# ISP_SBL register map
Vendor: Texas Instruments
Peripheral module from a debugger description file (folder omap36xx).
Registers are 32-bit, read-only, reset 0x0 unless marked. A register's access mark holds for its fields unless they carry their own. Offsets are as the file gives them; lines under a group give offsets from that group; [hi:lo] are bit positions; {n}, {i} and the like mark numbered series; 'fields as' and 'values as' point back to an identical list; <NAME> marks a mode.

## ISP_SBL
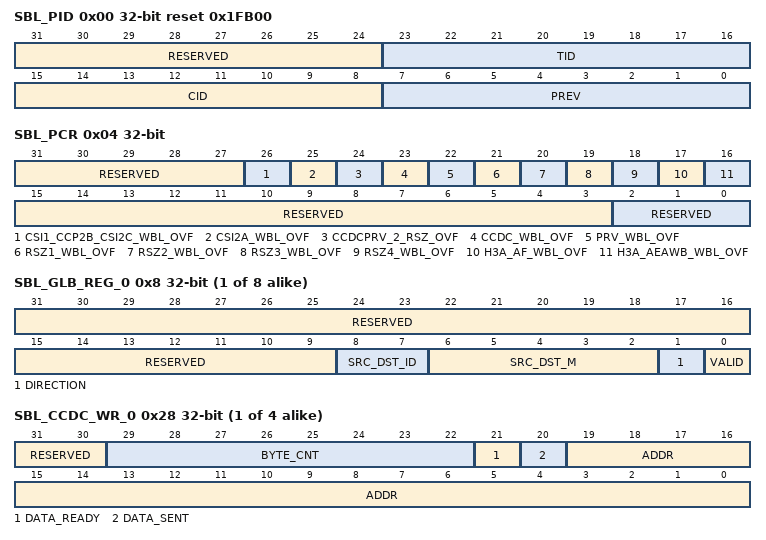
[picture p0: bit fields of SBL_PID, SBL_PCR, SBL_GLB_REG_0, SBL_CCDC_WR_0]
0x00 SBL_PID reset 0x1FB00 (reset mask 0xFFFFFF00) — PERIPHERAL IDENTIFICATION REGISTER
  [31:24] RESERVED — Write 0s for future compatibility. Reads returns 0.
  [23:16] TID — Peripheral identification: SBL module
  [15:8] CID — Class identification: Camera ISP
  [7:0] PREV — Peripheral revision number
0x04 SBL_PCR rw — PERIPHERAL CONTROL REGISTER Note on the overflow bits: the overflow does not prevent the modules to make further requests. The only way to clear the overflow is to reset the bit. After an overflow, the data will be corrupted and the application layer should disregard the data. No software reset is required after an overflow. If the overflow condition is cleread the data will continue to be acquired normally.
  [31:27] RESERVED — Write 0's for future compatibility.Reads returns 0.
  [26] CSI1_CCP2B_CSI2C_WBL_OVF — CSI1/CCP2B or CSI2C Write buffer memory overflow All DUs have been filled up: overflow.Software has to write 1 to clear the bit.
    0=CSI1_CCP2B_CSI2C_WBL_OVF_0_r (No overflow); 1=CSI1_CCP2B_CSI2C_WBL_OVF_1_r (Overflow)
  [25] CSI2A_WBL_OVF — CSI2A Write buffer memory overflow All DUs have been filled up: overflow. Software has to write 1 to clear the bit.
    0=CSI2A_WBL_OVF_0_r (No overflow); 1=CSI2A_WBL_OVF_1_r (Overflow)
  [24] CCDCPRV_2_RSZ_OVF — CCDC/PRV to RESIZER input overflow This bit is set if the RESIZER input source is set to CCDC/PREVIEW engine when the active data (to be resized) has already showed up at the resizer interface. In such a case, resizing for this frame cannot take place and the bit is set. This scenario can happen when a resize of 4x is required per frame. Therefore, the REISZER needs to operate in two passes. In the first pass the input data from CCDC/PREVIEW is directly resized and written to memory. In the second pass, the resized data from the first pass is resized again. The next frame from the CCDC/PREVIEW engine should only start after the second pass on the previous frame is complet. This bit indicated the failure status. Software has to write 1 to clear the bit. Ignore the behavior of this field when RSZ_CNT[28] INPSRC = 0x1 (when data comes from memory).
    0=CCDCPRV_2_RSZ_OVF_0_r (No overflow); 1=CCDCPRV_2_RSZ_OVF_1_r (Overflow)
  [23] CCDC_WBL_OVF — CCDC Write buffer memory overflow All DUs have been filled up: overflow. Software has to write 1 to clear the bit.
    0=CCDC_WBL_OVF_0_r (No overflow); 1=CCDC_WBL_OVF_1_r (Overflow)
  [22] PRV_WBL_OVF — PREVIEW Write buffer memory overflow All DUs have been filled up: overflow. Software has to write 1 to clear the bit.
    0=PRV_WBL_OVF_0_r (No overflow); 1=PRV_WBL_OVF_1_r (Overflow)
  [22-n] RSZ{n}_WBL_OVF (n=1..4) — RESIZER line {n} Write buffer memory overflow All DUs have been filled up: overflow. Software has to write 1 to clear the bit.
    0=RSZ{n}_WBL_OVF_0_r (No overflow); 1=RSZ{n}_WBL_OVF_1_r (Overflow)
  [17] H3A_AF_WBL_OVF — H3A AF Write buffer memory overflow All DUs have been filled up: overflow. Software has to write 1 to clear the bit.
    0=H3A_AF_WBL_OVF_0_r (No overflow); 1=H3A_AF_WBL_OVF_1_r (Overflow)
  [16] H3A_AEAWB_WBL_OVF — H3A AE AWB Write buffer memory overflow All DUs have been filled up: overflow. Software has to write 1 to clear the bit.
    0=H3A_AEAWB_WBL_OVF_0_r (No overflow); 1=H3A_AEAWB_WBL_OVF_1_r (Overflow)
  [15:3] RESERVED — Write 0's for future compatibility.Reads returns 0.
  [2:0] RESERVED — Write 0's for future compatibility.Reads returns 0.
{0x8+4i} SBL_GLB_REG_{i} (i=0..7) — GLOBAL REGISTER {i}
  [31:9] RESERVED — Write 0's for future compatibility.Reads returns 0.
  [8:7] SRC_DST_ID — Individual module register command number. For the modules that only have 2 individual requestors, this field will only display either 0 or 1. For modules that have 4 individual requestors, this field will display 0, 1, 2 or 3.
    {v}=SRC_DST_ID_{v}_r (Read / write module requestor #{v+1}) (v=0..3)
  [6:2] SRC_DST_M — Source or destination module
    0=SRC_DST_M_0_r (CCDC module ouput); 1=SRC_DST_M_1_r (CCDC module fault pixel correction input); 2=SRC_DST_M_2_r (PREVIEW module input); 3=SRC_DST_M_3_r (PREVIEW module ouput); 4=SRC_DST_M_4_r (PREVIEW module dark frame subtract input); 5=SRC_DST_M_5_r (RESIZER module input); {v}=SRC_DST_M_{v}_r (RESIZER module output line {v-5}) (v=6..9); 10=SRC_DST_M_10_r (HISTOGRAM module input); 11=SRC_DST_M_11_r (H3A module output - auto focus); 12=SRC_DST_M_12_r (H3A module output - auto exposure and auto white balance); 13=SRC_DST_M_13_r (CSI2A module output); 14=SRC_DST_M_14_r (CSI1/CCP2B or CSI2C module output)
  [1] DIRECTION
    0=DIRECTION_0_r (Read); 1=DIRECTION_1_r (Write)
  [0] VALID — Valid bit
    0=VALID_0_r (Not valid.); 1=VALID_1_r
{0x28+4i} SBL_CCDC_WR_{i} (i=0..3) — CCDC WRITE REQUEST {i+1} REGISTER
  [31:30] RESERVED — Write 0's for future compatibility.Reads returns 0.
  [29:22] BYTE_CNT — Current byte count.
  [21] DATA_READY
    0=DATA_READY_0_r (No); 1=DATA_READY_1_r (Yes)
  [20] DATA_SENT — Data sent to the destination, waiting for status.
    0=DATA_SENT_0_r (No); 1=DATA_SENT_1_r (Yes)
  [19:0] ADDR — Upper 20 bits of the write address.
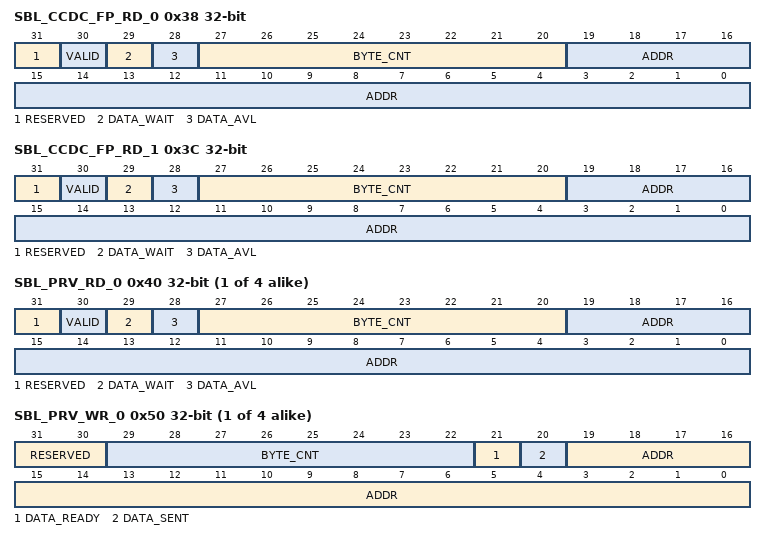
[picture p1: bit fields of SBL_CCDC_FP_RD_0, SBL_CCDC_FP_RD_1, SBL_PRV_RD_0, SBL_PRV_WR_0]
0x38 SBL_CCDC_FP_RD_0 — CCDC FAULT PIXEL CORRECTION READ REQUEST 1 REGISTER
  [31] RESERVED — Write 0's for future compatibility.Reads returns 0.
  [30] VALID — Valid bit
    0=VALID_0_r (No); 1=VALID_1_r (Yes)
  [29] DATA_WAIT — Waiting for data
    0=DATA_WAIT_0_r (No); 1=DATA_WAIT_1_r (Yes)
  [28] DATA_AVL — Data available. Received from source and can be read by the module.
    0=DATA_AVL_0_r (No); 1=DATA_AVL_1_r (Yes)
  [27:20] BYTE_CNT — Byte count requested.
  [19:0] ADDR — Upper 20 bits of the read address.
0x3C SBL_CCDC_FP_RD_1 — CCDC FAULT PIXEL CORRECTION READ REQUEST 2 REGISTER
  fields as SBL_CCDC_FP_RD_0
{0x40+4i} SBL_PRV_RD_{i} (i=0..3) — PREVIEW READ REQUEST {i+1} REGISTER
  fields as SBL_CCDC_FP_RD_0
{0x50+4i} SBL_PRV_WR_{i} (i=0..3) — PREVIEW WRITE REQUEST {i+1} REGISTER
  fields as SBL_CCDC_WR_0
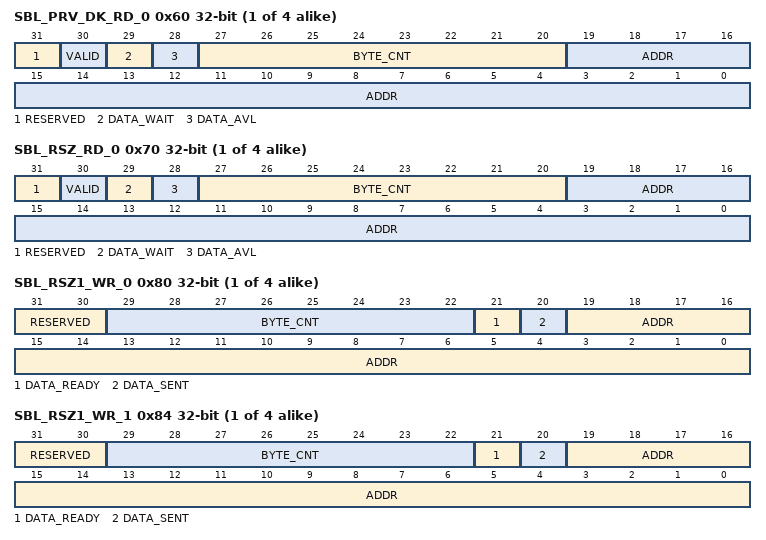
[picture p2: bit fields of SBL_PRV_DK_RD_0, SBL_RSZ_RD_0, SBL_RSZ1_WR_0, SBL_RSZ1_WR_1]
{0x60+4i} SBL_PRV_DK_RD_{i} (i=0..3) — PREVIEW DARK FRAME READ REQUEST {i+1} REGISTER
  fields as SBL_CCDC_FP_RD_0
{0x70+4i} SBL_RSZ_RD_{i} (i=0..3) — RESIZER READ REQUEST {i+1} REGISTER
  fields as SBL_CCDC_FP_RD_0
{0x70+0x10*i} SBL_RSZ{i}_WR_0 (i=1..4) — RESIZER LINE {i} WRITE REQUEST 1 REGISTER
  fields as SBL_CCDC_WR_0
{0x74+0x10*i} SBL_RSZ{i}_WR_1 (i=1..4) — RESIZER LINE {i} WRITE REQUEST 2 REGISTER
  fields as SBL_CCDC_WR_0
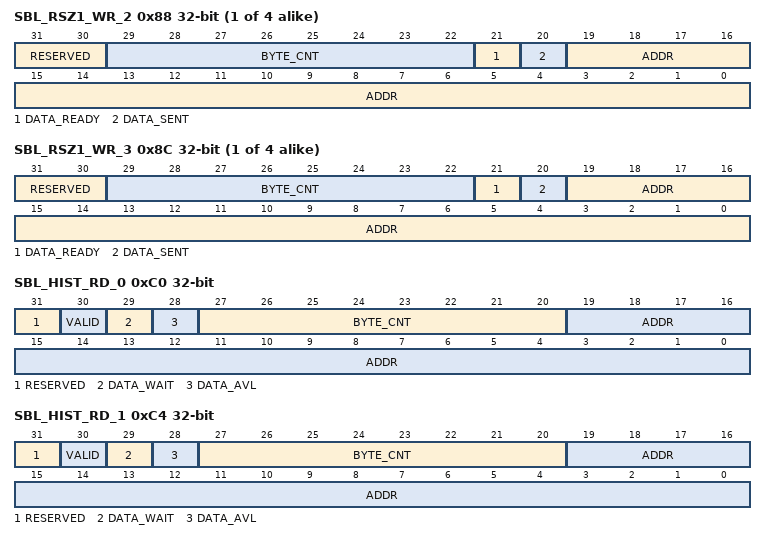
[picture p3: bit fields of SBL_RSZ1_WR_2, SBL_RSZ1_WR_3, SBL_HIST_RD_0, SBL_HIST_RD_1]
{0x78+0x10*i} SBL_RSZ{i}_WR_2 (i=1..4) — RESIZER LINE {i} WRITE REQUEST 3 REGISTER
  fields as SBL_CCDC_WR_0
{0x7C+0x10*i} SBL_RSZ{i}_WR_3 (i=1..4) — RESIZER LINE {i} WRITE REQUEST 4 REGISTER
  fields as SBL_CCDC_WR_0
0xC0 SBL_HIST_RD_0 — HISTOGRAM READ REQUEST 1 REGISTER
  fields as SBL_CCDC_FP_RD_0
0xC4 SBL_HIST_RD_1 — HISTOGRAM READ REQUEST 2 REGISTER
  fields as SBL_CCDC_FP_RD_0
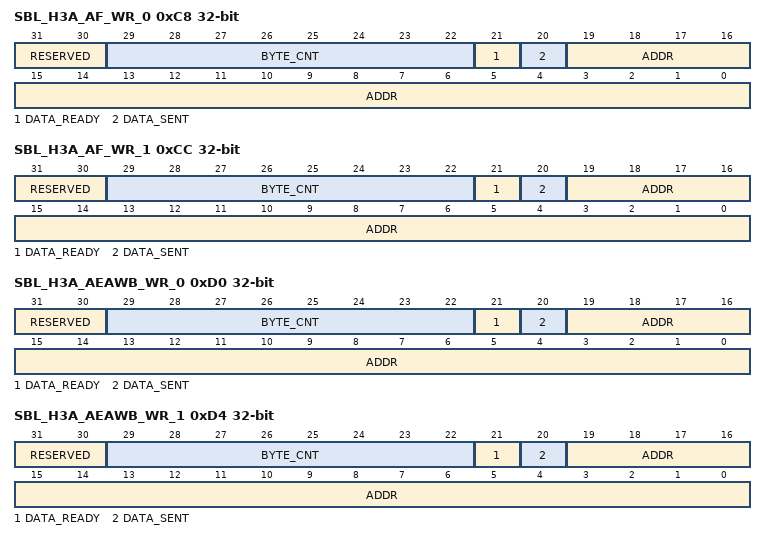
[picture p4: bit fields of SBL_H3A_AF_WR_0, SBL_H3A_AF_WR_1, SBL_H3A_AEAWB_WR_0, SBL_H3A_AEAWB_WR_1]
0xC8 SBL_H3A_AF_WR_0 — H3A AF WRITE REQUEST 1 REGISTER
  fields as SBL_CCDC_WR_0
0xCC SBL_H3A_AF_WR_1 — H3A AF WRITE REQUEST 2 REGISTER
  fields as SBL_CCDC_WR_0
0xD0 SBL_H3A_AEAWB_WR_0 — H3A AE AWB WRITE REQUEST 1 REGISTER
  fields as SBL_CCDC_WR_0
0xD4 SBL_H3A_AEAWB_WR_1 — H3A AE AWB WRITE REQUEST 2 REGISTER
  fields as SBL_CCDC_WR_0
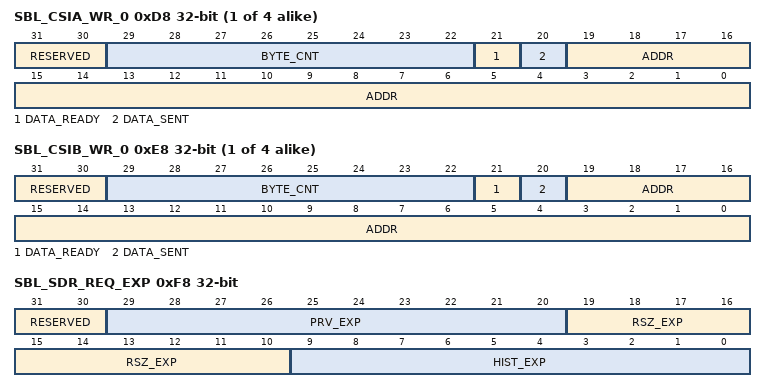
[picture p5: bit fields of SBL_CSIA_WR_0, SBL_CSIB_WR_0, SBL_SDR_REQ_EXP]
{0xD8+4i} SBL_CSIA_WR_{i} (i=0..3) — CSIA WRITE REQUEST {i+1} REGISTER
  fields as SBL_CCDC_WR_0
{0xE8+4i} SBL_CSIB_WR_{i} (i=0..3) — CSIB WRITE REQUEST {i+1} REGISTER
  fields as SBL_CCDC_WR_0
0xF8 SBL_SDR_REQ_EXP rw — MEMORY NON REAL TIME READ REQUEST EXPAND
  [31:30] RESERVED — Write 0s for future compatibility. Read returns 0.
  [29:20] PRV_EXP — PREVIEW module READ request expand Sets the number of clock cycles (func clock cycles) to allow btw two consecutive READ requests from the module. It spreads non-real time read requests over time. It enables less priority in the system not to be locked out. At maximum, the PRV and CCP2_RD can read 256 bytes every 32*PRV_EXP functional clock cycles.
  [19:10] RSZ_EXP — RESIZER module READ request expand Sets the number of clock cycles (func clock cycles) to allow btw two consecutive READ requests from the module. It spreads non-real time read requests over time. It enables less priority in the system not to be locked out. At maximum, the RSZ can read 256 bytes every 32*RSZ_EXP functional clock cycles.
  [9:0] HIST_EXP — HISTOGRAM module READ request expand Sets the number of clock cycles to allow btw two consecutive READ requests from the module. It spreads non-real time read requests over time. It enables less priority in the system not to be locked out. At maximum, the HIST can read 256 bytes every HIST_EXP functional clock cycles.
